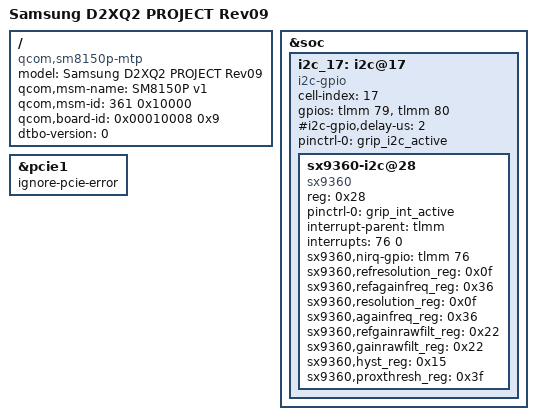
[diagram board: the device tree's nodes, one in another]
/* Copyright (c) 2016-2017, The Linux Foundation. All rights reserved.
 *
 * This program is free software; you can redistribute it and/or modify
 * it under the terms of the GNU General Public License version 2 and
 * only version 2 as published by the Free Software Foundation.
 *
 * This program is distributed in the hope that it will be useful,
 * but WITHOUT ANY WARRANTY; without even the implied warranty of
 * MERCHANTABILITY or FITNESS FOR A PARTICULAR PURPOSE.  See the
 * GNU General Public License for more details.
 */

/dts-v1/;
/plugin/;

#include <dt-bindings/clock/qcom,gcc-sm8150.h>
#include <dt-bindings/clock/qcom,camcc-sm8150.h>
#include <dt-bindings/clock/qcom,rpmh.h>
#include <dt-bindings/interrupt-controller/arm-gic.h>

#include "../qcom/sm8150-mtp.dtsi"
#include "../qcom/sdx5xm-external-soc.dtsi"
#include "../qcom/sm8150-sdxprairie.dtsi"
#include "sm8150-sec-common.dtsi"
#include "sm8150-sec-d2xq-pm-common.dtsi"
#include "sm8150-sec-d2xq-pm-r04.dtsi"
#include "sm8150p-sec-d2xq2-r09.dtsi"
#include "sm8150p-sec-d2xq2-pinctrl-r09.dtsi"
#include "sm8150-sec-d2xq-display-r00.dtsi"
#include "sm8150-sec-d2xq-displayport-r03.dtsi"
#include "battery-data-d2xq-sub6-r09.dtsi"
#include "sm8150-max77705.dtsi"
#include "sm8150-cs40l2x-d2xq-sub6-r01.dtsi"
#include "sm8150-sec-beyond2qlte-sensor-common.dtsi"
#include "sm8150-sec-davincixq-fingerprint-sensor-r00.dtsi"
#include "sm8150p-camera-sensor-d2xq-r00.dtsi"
#include "sm8150-sec-d2xq-nfc-r00.dtsi"
#include "sm8150-sec-d2xq-mst.dtsi"

/ {
	model = "Samsung D2XQ2 PROJECT Rev09";
	compatible = "qcom,sm8150p-mtp", "qcom,sm8150p", "qcom,mtp";
	qcom,msm-name = "SM8150P v1";
	qcom,msm-id = <361 0x10000>;
	qcom,board-id = <0x00010008 0x9>;
	dtbo-version = <0>;
};

/delete-node/ &i2c_17;

&soc {
	i2c_17: i2c@17 { /* SW I2C */
		status = "ok";

		cell-index = <17>;
		compatible = "i2c-gpio";
		gpios = <&tlmm 79 0 /* sda */
			 &tlmm 80 0 /* scl */
		>;
		#i2c-gpio,delay-us = <2>;
		#address-cells = <1>;
		#size-cells = <0>;
		pinctrl-names = "default";
		pinctrl-0 = <&grip_i2c_active>;

		sx9360-i2c@28 {
			compatible = "sx9360";
			reg = <0x28>;
			status = "okay";
			pinctrl-names = "default";
			pinctrl-0 = <&grip_int_active>;
			interrupt-parent = <&tlmm>;
			interrupts = <76 0>;

			sx9360,nirq-gpio = <&tlmm 76 0>;
			sx9360,refresolution_reg = <0x0f>; /* same as resolution_reg */
			sx9360,refagainfreq_reg = <0x36>; /* same as againfreq_reg */
			sx9360,resolution_reg = <0x0f>; /* resolution : 1024 */
			sx9360,againfreq_reg = <0x36>; /* freq : 83.33 kHz, again : +/-5.25 pF */
			sx9360,refgainrawfilt_reg = <0x22>; /* same as gainrawfilt_reg */
			sx9360,gainrawfilt_reg = <0x22>; /* rawfilter : 1-1/4, gain : x8 */
			sx9360,hyst_reg = <0x15>; /* hysteresis : +/-6 %, debouncer : 2 samples */
			sx9360,proxthresh_reg = <0x3f>; /* threshhold : 1984 */
		};
	};
};

&pcie1{
	ignore-pcie-error;
};
